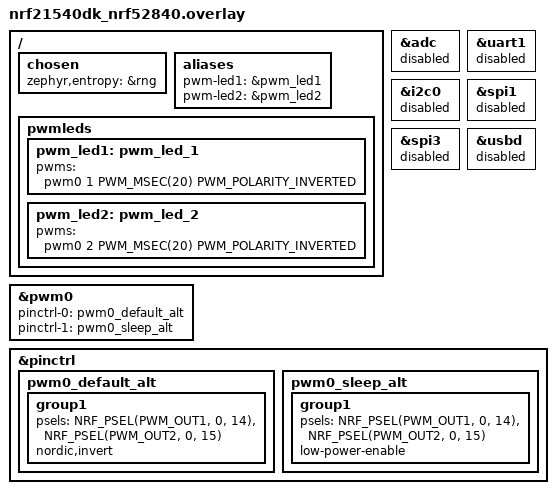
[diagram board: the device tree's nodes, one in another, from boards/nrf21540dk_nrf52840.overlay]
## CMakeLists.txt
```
#
# Copyright (c) 2022 Nordic Semiconductor ASA
#
# SPDX-License-Identifier: LicenseRef-Nordic-5-Clause
#

cmake_minimum_required(VERSION 3.20.0)

find_package(Zephyr HINTS $ENV{ZEPHYR_BASE})

project(matter-window-app)

# Enable GNU STD support and initialize the Matter Data Model.
include(${ZEPHYR_CONNECTEDHOMEIP_MODULE_DIR}/config/nrfconnect/app/enable-gnu-std.cmake)
include(${ZEPHYR_CONNECTEDHOMEIP_MODULE_DIR}/src/app/chip_data_model.cmake)

# NORDIC SDK APP START

# Include all source files that are located in the Matter common directory.
include(${ZEPHYR_NRF_MODULE_DIR}/samples/matter/common/cmake/source_common.cmake)

target_include_directories(app PRIVATE
    src
    ${CONFIG_NCS_SAMPLE_MATTER_ZAP_FILES_PATH}
)

target_sources(app PRIVATE
    src/app_task.cpp
    src/window_covering.cpp
    src/main.cpp
    src/zcl_callbacks.cpp
)

chip_configure_data_model(app
    INCLUDE_SERVER
    BYPASS_IDL
    GEN_DIR ${CONFIG_NCS_SAMPLE_MATTER_ZAP_FILES_PATH}/zap-generated
    ZAP_FILE ${CMAKE_CURRENT_SOURCE_DIR}/${CONFIG_NCS_SAMPLE_MATTER_ZAP_FILES_PATH}/window-app.zap
)
# NORDIC SDK APP END
```

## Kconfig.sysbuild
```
#
# Copyright (c) 2023 Nordic Semiconductor ASA
#
# SPDX-License-Identifier: LicenseRef-Nordic-5-Clause
#

config WIFI_NRF70
	default y if BOARD_NRF7002DK

#### Radio core selection
config NRF_DEFAULT_IPC_RADIO
	default y

# Enable IEEE802.15.4 serialization to network core
# This config automatically pulls in the `overlay-802154.conf` in the ipc_radio image
config NETCORE_IPC_RADIO_IEEE802154
	default y if SOC_SERIES_NRF53X && !WIFI_NRF70

# Enable Bluetooth serialization to network core
# This config automatically pulls in the `overlay-bt_hci_ipc.conf` in the ipc_radio image
config NETCORE_IPC_RADIO_BT_HCI_IPC
	default y if SOC_SERIES_NRF53X

#### Bootloader
choice BOOTLOADER
	default BOOTLOADER_MCUBOOT if !BOARD_NRF21540DK
endchoice

if BOOTLOADER_MCUBOOT

#### DFU multi-image support
config DFU_MULTI_IMAGE_PACKAGE_BUILD
	default y

config DFU_MULTI_IMAGE_PACKAGE_APP
	default y

config PM_EXTERNAL_FLASH_MCUBOOT_SECONDARY
	default y

#### DFU network core configuration
if SOC_SERIES_NRF53X

config MCUBOOT_UPDATEABLE_IMAGES
	default 2

choice MCUBOOT_MODE
	default MCUBOOT_MODE_OVERWRITE_ONLY
endchoice

choice BOOT_SIGNATURE_TYPE
	default BOOT_SIGNATURE_TYPE_RSA
endchoice

config SECURE_BOOT_NETCORE
	default y

config NETCORE_APP_UPDATE
	default y

config DFU_MULTI_IMAGE_PACKAGE_NET
	default y

endif # SOC_SERIES_NRF53X

if BOARD_NRF54L15DK_NRF54L15_CPUAPP_NS

# Disable checking the external drivers for NS build.
config PM_OVERRIDE_EXTERNAL_DRIVER_CHECK
	default y

# override the mcuboot pad size, because it is not set globally for NS build.
config PM_MCUBOOT_PAD
	default 0x800

endif # BOARD_NRF54L15DK_NRF54L15_CPUAPP_NS

endif # BOOTLOADER_MCUBOOT

#### Enable generating factory data
config MATTER_FACTORY_DATA_GENERATE
	default y if !BOARD_NRF21540DK

source "${ZEPHYR_BASE}/share/sysbuild/Kconfig"
```

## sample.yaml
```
sample:
  description: Matter Window Covering example
  name: Matter Window Covering
tests:
  sample.matter.window_cover.debug:
    sysbuild: true
    build_only: true
    integration_platforms:
      - nrf52840dk/nrf52840
      - nrf5340dk/nrf5340/cpuapp
      - nrf54l15dk/nrf54l15/cpuapp
      - nrf54l15dk/nrf54l15/cpuapp/ns
    platform_allow: nrf52840dk/nrf52840 nrf5340dk/nrf5340/cpuapp
      nrf54l15dk/nrf54l15/cpuapp nrf54l15dk/nrf54l15/cpuapp/ns
    tags: sysbuild ci_samples_matter
  sample.matter.window_cover.release:
    sysbuild: true
    build_only: true
    extra_args: FILE_SUFFIX=release
      SB_CONFIG_BOOTLOADER_MCUBOOT=y SB_CONFIG_PARTITION_MANAGER=y
    integration_platforms:
      - nrf52840dk/nrf52840
      - nrf5340dk/nrf5340/cpuapp
      - nrf54l15dk/nrf54l15/cpuapp
    platform_allow: nrf52840dk/nrf52840 nrf5340dk/nrf5340/cpuapp
      nrf54l15dk/nrf54l15/cpuapp
    tags: sysbuild ci_samples_matter
  sample.matter.window_cover.lto:
    sysbuild: true
    build_only: true
    extra_args: CONFIG_LTO=y CONFIG_ISR_TABLES_LOCAL_DECLARATION=y
    integration_platforms:
      - nrf52840dk/nrf52840
      - nrf5340dk/nrf5340/cpuapp
      - nrf54l15dk/nrf54l15/cpuapp
    platform_allow: nrf52840dk/nrf52840 nrf5340dk/nrf5340/cpuapp
      nrf54l15dk/nrf54l15/cpuapp
    tags: sysbuild ci_samples_matter
  sample.matter.window_cover.release.nrf54l15.power_consumption:
    sysbuild: true
    build_only: true
    extra_args: FILE_SUFFIX=release CONFIG_NCS_SAMPLE_MATTER_LEDS=n
      CONFIG_NCS_SAMPLE_MATTER_WATCHDOG=n
    integration_platforms:
      - nrf54l15dk/nrf54l15/cpuapp
    platform_allow: nrf54l15dk/nrf54l15/cpuapp
    tags: sysbuild ci_samples_matter
```

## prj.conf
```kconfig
#
# Copyright (c) 2022 Nordic Semiconductor ASA
#
# SPDX-License-Identifier: LicenseRef-Nordic-5-Clause
#

# This sample uses Kconfig.defaults to set options common for all
# samples. This file should contain only options specific for this sample
# or overrides of default values.

# Enable CHIP
CONFIG_CHIP=y
CONFIG_CHIP_PROJECT_CONFIG="src/chip_project_config.h"
# 32784 == 0x8010 (example window-app)
CONFIG_CHIP_DEVICE_PRODUCT_ID=32784
CONFIG_STD_CPP17=y

# Enable Matter pairing automatically on application start.
CONFIG_CHIP_ENABLE_PAIRING_AUTOSTART=y

# Enable Matter extended announcement and increase duration to 1 hour.
CONFIG_CHIP_BLE_EXT_ADVERTISING=y
CONFIG_CHIP_BLE_ADVERTISING_DURATION=60

# Add support for LEDs and buttons on Nordic development kits
CONFIG_DK_LIBRARY=y

# PWM support
CONFIG_PWM=y

# OpenThread configs
CONFIG_OPENTHREAD_NORDIC_LIBRARY_MTD=y
CONFIG_OPENTHREAD_MTD=y
CONFIG_OPENTHREAD_FTD=n
CONFIG_CHIP_ENABLE_ICD_SUPPORT=y
CONFIG_CHIP_THREAD_SSED=y
CONFIG_CHIP_ICD_SLOW_POLL_INTERVAL=500
CONFIG_CHIP_ICD_FAST_POLLING_INTERVAL=500

# Bluetooth Low Energy configuration
CONFIG_BT_DEVICE_NAME="MatterWinCov"

# Suspend devices when the CPU goes into sleep
CONFIG_PM_DEVICE=y

# Stack size settings
CONFIG_IEEE802154_NRF5_RX_STACK_SIZE=1024

# Other settings
CONFIG_THREAD_NAME=y
CONFIG_MPU_STACK_GUARD=y
CONFIG_RESET_ON_FATAL_ERROR=n
CONFIG_CHIP_LIB_SHELL=y
CONFIG_NCS_SAMPLE_MATTER_TEST_SHELL=y

# Reduce application size
CONFIG_USE_SEGGER_RTT=n

# Enable Factory Data feature
CONFIG_CHIP_FACTORY_DATA=y
CONFIG_CHIP_FACTORY_DATA_BUILD=y
```

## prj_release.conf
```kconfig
#
# Copyright (c) 2022 Nordic Semiconductor ASA
#
# SPDX-License-Identifier: LicenseRef-Nordic-5-Clause
#

# This sample uses Kconfig.defaults to set options common for all
# samples. This file should contain only options specific for this sample
# or overrides of default values.

# Enable CHIP
CONFIG_CHIP=y
CONFIG_CHIP_PROJECT_CONFIG="src/chip_project_config.h"
# 32784 == 0x8010 (example window-app)
CONFIG_CHIP_DEVICE_PRODUCT_ID=32784
CONFIG_STD_CPP17=y

# Enable Matter pairing automatically on application start.
CONFIG_CHIP_ENABLE_PAIRING_AUTOSTART=y

# Enable Matter extended announcement and increase duration to 1 hour.
CONFIG_CHIP_BLE_EXT_ADVERTISING=y
CONFIG_CHIP_BLE_ADVERTISING_DURATION=60

# Add support for LEDs and buttons on Nordic development kits
CONFIG_DK_LIBRARY=y

# Try to disable unused RAM blocks to reduce power consumption
CONFIG_RAM_POWER_DOWN_LIBRARY=y

# PWM support
CONFIG_PWM=y

# OpenThread configs
CONFIG_OPENTHREAD_NORDIC_LIBRARY_MTD=y
CONFIG_OPENTHREAD_MTD=y
CONFIG_OPENTHREAD_FTD=n
CONFIG_CHIP_ENABLE_ICD_SUPPORT=y
CONFIG_CHIP_THREAD_SSED=y
CONFIG_CHIP_ICD_SLOW_POLL_INTERVAL=500
CONFIG_CHIP_ICD_FAST_POLLING_INTERVAL=500

# Bluetooth Low Energy configuration
CONFIG_BT_DEVICE_NAME="MatterWinCov"

# Suspend devices when the CPU goes into sleep
CONFIG_PM_DEVICE=y

# Stack size settings
CONFIG_IEEE802154_NRF5_RX_STACK_SIZE=1024

# Enable system reset on fatal error
CONFIG_RESET_ON_FATAL_ERROR=y

# Disable all debug features
CONFIG_USE_SEGGER_RTT=n
CONFIG_SHELL=n
CONFIG_OPENTHREAD_SHELL=n
CONFIG_CONSOLE=n
CONFIG_UART_CONSOLE=n
CONFIG_SERIAL=n
CONFIG_LOG=n
CONFIG_LOG_MODE_MINIMAL=n
CONFIG_ASSERT_VERBOSE=n
CONFIG_ASSERT_NO_FILE_INFO=y
CONFIG_PRINTK=n
CONFIG_PRINTK_SYNC=n
CONFIG_THREAD_NAME=n
CONFIG_BOOT_BANNER=n

# Enable Factory Data feature
CONFIG_CHIP_FACTORY_DATA=y
CONFIG_CHIP_FACTORY_DATA_BUILD=y

# Enable Watchdog
CONFIG_NCS_SAMPLE_MATTER_WATCHDOG=y
```

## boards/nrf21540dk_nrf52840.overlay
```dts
/* Copyright (c) 2021 Nordic Semiconductor ASA
 *
 * SPDX-License-Identifier: LicenseRef-Nordic-5-Clause
 */

/ {
	/*
	* In some default configurations within the nRF Connect SDK,
	* e.g. on nRF52840, the chosen zephyr,entropy node is &cryptocell.
	* This devicetree overlay ensures that default is overridden wherever it
	* is set, as this application uses the RNG node for entropy exclusively.
	*/
	chosen {
		zephyr,entropy = &rng;
	};

	/*
	* Configure LED2 and LED3 to show the state of the
	* window cover,by using the LED's brightness level.
	*/
	aliases {
		pwm-led1 = &pwm_led1;
		pwm-led2 = &pwm_led2;
	};

	pwmleds {
		pwm_led1: pwm_led_1 {
			pwms = <&pwm0 1 PWM_MSEC(20) PWM_POLARITY_INVERTED>;
		};
		pwm_led2: pwm_led_2 {
			pwms = <&pwm0 2 PWM_MSEC(20) PWM_POLARITY_INVERTED>;
		};
	};
};

/* Disable unused peripherals to reduce power consumption */
&adc {
	status = "disabled";
};
&uart1 {
	status = "disabled";
};
&i2c0 {
	status = "disabled";
};
&spi1 {
	status = "disabled";
};
&spi3 {
	status = "disabled";
};
&usbd {
	status = "disabled";
};

&pwm0 {
	pinctrl-0 = <&pwm0_default_alt>;
	pinctrl-1 = <&pwm0_sleep_alt>;
	pinctrl-names = "default", "sleep";
};

&pinctrl {
	pwm0_default_alt: pwm0_default_alt {
		group1 {
			psels = <NRF_PSEL(PWM_OUT1, 0, 14)>, <NRF_PSEL(PWM_OUT2, 0, 15)>;
			nordic,invert;
		};
	};

	pwm0_sleep_alt: pwm0_sleep_alt {
		group1 {
			psels = <NRF_PSEL(PWM_OUT1, 0, 14)>, <NRF_PSEL(PWM_OUT2, 0, 15)>;
			low-power-enable;
		};
	};
};
```

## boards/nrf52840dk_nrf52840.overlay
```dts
/* Copyright (c) 2021 Nordic Semiconductor ASA
 *
 * SPDX-License-Identifier: LicenseRef-Nordic-5-Clause
 */

/ {
	chosen {
		nordic,pm-ext-flash = &mx25r64;
	};
};


/ {
	/*
	* In some default configurations within the nRF Connect SDK,
	* e.g. on nRF52840, the chosen zephyr,entropy node is &cryptocell.
	* This devicetree overlay ensures that default is overridden wherever it
	* is set, as this application uses the RNG node for entropy exclusively.
	*/
	chosen {
		zephyr,entropy = &rng;
	};

	/*
	* Configure LED2 and LED3 to show the state of the
	* window cover,by using the LED's brightness level.
	*/
	aliases {
		pwm-led1 = &pwm_led1;
		pwm-led2 = &pwm_led2;
	};

	pwmleds {
		pwm_led1: pwm_led_1 {
			pwms = <&pwm0 1 PWM_MSEC(20) PWM_POLARITY_INVERTED>;
		};
		pwm_led2: pwm_led_2 {
			pwms = <&pwm0 2 PWM_MSEC(20) PWM_POLARITY_INVERTED>;
		};
	};
};

/* Disable unused peripherals to reduce power consumption */
&adc {
	status = "disabled";
};
&uart1 {
	status = "disabled";
};
&i2c0 {
	status = "disabled";
};
&spi1 {
	status = "disabled";
};
&spi3 {
	status = "disabled";
};
&usbd {
	status = "disabled";
};

&pwm0 {
	pinctrl-0 = <&pwm0_default_alt>;
	pinctrl-1 = <&pwm0_sleep_alt>;
	pinctrl-names = "default", "sleep";
};

&pinctrl {
	pwm0_default_alt: pwm0_default_alt {
		group1 {
			psels = <NRF_PSEL(PWM_OUT1, 0, 14)>, <NRF_PSEL(PWM_OUT2, 0, 15)>;
			nordic,invert;
		};
	};

	pwm0_sleep_alt: pwm0_sleep_alt {
		group1 {
			psels = <NRF_PSEL(PWM_OUT1, 0, 14)>, <NRF_PSEL(PWM_OUT2, 0, 15)>;
			low-power-enable;
		};
	};
};
```

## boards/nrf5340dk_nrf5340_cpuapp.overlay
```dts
/*
 * Copyright (c) 2021 Nordic Semiconductor ASA
 *
 * SPDX-License-Identifier: LicenseRef-Nordic-5-Clause
 */

#include <zephyr/dt-bindings/ipc_service/static_vrings.h>

/ {
	chosen {
		nordic,pm-ext-flash = &mx25r64;
	};

	/*
	* Configure LED2 and LED3 to show the state of the
	* window cover,by using the LED's brightness level.
	*/
	aliases {
		pwm-led1 = &pwm_led1;
		pwm-led2 = &pwm_led2;
	};

	pwmleds {
		compatible = "pwm-leds";
		pwm_led1: pwm_led_1 {
			pwms = <&pwm0 1 PWM_MSEC(20) PWM_POLARITY_INVERTED>;
		};
		pwm_led2: pwm_led_2 {
			pwms = <&pwm0 2 PWM_MSEC(20) PWM_POLARITY_INVERTED>;
		};
	};
};

/* Set IPC thread priority to the highest value to not collide with other threads. */
&ipc0 {
    zephyr,priority = <0 PRIO_COOP>;
};

/* Disable unused peripherals to reduce power consumption */
&adc {
	status = "disabled";
};
&i2c1 {
	status = "disabled";
};
&spi2 {
	status = "disabled";
};
&usbd {
	status = "disabled";
};

&pwm0 {
	pinctrl-0 = <&pwm0_default_alt>;
	pinctrl-1 = <&pwm0_sleep_alt>;
	pinctrl-names = "default", "sleep";
};

&pinctrl {
	pwm0_default_alt: pwm0_default_alt {
		group1 {
			psels = <NRF_PSEL(PWM_OUT1, 0, 29)>, <NRF_PSEL(PWM_OUT2, 0, 30)>;
			nordic,invert;
		};
	};

	pwm0_sleep_alt: pwm0_sleep_alt {
		group1 {
			psels = <NRF_PSEL(PWM_OUT1, 0, 29)>, <NRF_PSEL(PWM_OUT2, 0, 30)>;
			low-power-enable;
		};
	};
};
```

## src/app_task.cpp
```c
/*
 * Copyright (c) 2022 Nordic Semiconductor ASA
 *
 * SPDX-License-Identifier: LicenseRef-Nordic-5-Clause
 */

#include "app_task.h"

#include "window_covering.h"

#include "app/matter_init.h"
#include "app/task_executor.h"

#ifdef CONFIG_CHIP_OTA_REQUESTOR
#include "dfu/ota/ota_util.h"
#endif

#include <app/clusters/identify-server/identify-server.h>
#include <app/server/OnboardingCodesUtil.h>

#include <zephyr/logging/log.h>

LOG_MODULE_DECLARE(app, CONFIG_CHIP_APP_LOG_LEVEL);

using namespace ::chip;
using namespace ::chip::app;
using namespace ::chip::DeviceLayer;

namespace
{
Identify sIdentify = { WindowCovering::Endpoint(), AppTask::IdentifyStartHandler, AppTask::IdentifyStopHandler,
		       Clusters::Identify::IdentifyTypeEnum::kVisibleIndicator };

#define OPEN_BUTTON_MASK DK_BTN2_MSK
#define CLOSE_BUTTON_MASK DK_BTN3_MSK
} /* namespace */

void AppTask::IdentifyStartHandler(Identify *)
{
	Nrf::PostTask([] {
		WindowCovering::Instance().GetLiftIndicator().SuppressOutput();
		Nrf::GetBoard().GetLED(Nrf::DeviceLeds::LED2).Blink(Nrf::LedConsts::kIdentifyBlinkRate_ms);
	});
}

void AppTask::IdentifyStopHandler(Identify *)
{
	Nrf::PostTask([] {
		Nrf::GetBoard().GetLED(Nrf::DeviceLeds::LED2).Set(false);
		WindowCovering::Instance().GetLiftIndicator().ApplyLevel();
	});
}

void AppTask::ButtonEventHandler(Nrf::ButtonState state, Nrf::ButtonMask hasChanged)
{
	if (OPEN_BUTTON_MASK & hasChanged) {
		WindowButtonAction action =
			(OPEN_BUTTON_MASK & state) ? WindowButtonAction::Pressed : WindowButtonAction::Released;
		Nrf::PostTask([action] { OpenHandler(action); });
	}

	if (CLOSE_BUTTON_MASK & hasChanged) {
		WindowButtonAction action =
			(CLOSE_BUTTON_MASK & state) ? WindowButtonAction::Pressed : WindowButtonAction::Released;
		Nrf::PostTask([action] { CloseHandler(action); });
	}
}

void AppTask::OpenHandler(const WindowButtonAction &action)
{
	if (action == WindowButtonAction::Pressed) {
		Instance().mOpenButtonIsPressed = true;
		if (Instance().mCloseButtonIsPressed) {
			Instance().ToggleMoveType();
		}
	} else {
		if (!Instance().mCloseButtonIsPressed) {
			if (!Instance().mMoveTypeRecentlyChanged) {
				WindowCovering::Instance().SetSingleStepTarget(OperationalState::MovingUpOrOpen);
			} else {
				Instance().mMoveTypeRecentlyChanged = false;
			}
		}
		Instance().mOpenButtonIsPressed = false;
	}
}

void AppTask::CloseHandler(const WindowButtonAction &action)
{
	if (action == WindowButtonAction::Pressed) {
		Instance().mCloseButtonIsPressed = true;
		if (Instance().mOpenButtonIsPressed) {
			Instance().ToggleMoveType();
		}
	} else {
		if (!Instance().mOpenButtonIsPressed) {
			if (!Instance().mMoveTypeRecentlyChanged) {
				WindowCovering::Instance().SetSingleStepTarget(OperationalState::MovingDownOrClose);
			} else {
				Instance().mMoveTypeRecentlyChanged = false;
			}
		}
		Instance().mCloseButtonIsPressed = false;
	}
}

void AppTask::ToggleMoveType()
{
	if (WindowCovering::Instance().GetMoveType() == WindowCovering::MoveType::LIFT) {
		WindowCovering::Instance().SetMoveType(WindowCovering::MoveType::TILT);
		LOG_INF("Window covering move: tilt");
	} else {
		WindowCovering::Instance().SetMoveType(WindowCovering::MoveType::LIFT);
		LOG_INF("Window covering move: lift");
	}
	mMoveTypeRecentlyChanged = true;
}

CHIP_ERROR AppTask::Init()
{
	/* Initialize Matter stack */
	ReturnErrorOnFailure(Nrf::Matter::PrepareServer(Nrf::Matter::InitData{ .mPostServerInitClbk = [] {
		WindowCovering::Instance().PositionLEDUpdate(WindowCovering::MoveType::LIFT);
		WindowCovering::Instance().PositionLEDUpdate(WindowCovering::MoveType::TILT);
		return CHIP_NO_ERROR;
	} }));

	if (!Nrf::GetBoard().Init(ButtonEventHandler)) {
		LOG_ERR("User interface initialization failed.");
		return CHIP_ERROR_INCORRECT_STATE;
	}

	/* Register Matter event handler that controls the connectivity status LED based on the captured Matter network
	 * state. */
	ReturnErrorOnFailure(Nrf::Matter::RegisterEventHandler(Nrf::Board::DefaultMatterEventHandler, 0));

	return Nrf::Matter::StartServer();
}

CHIP_ERROR AppTask::StartApp()
{
	ReturnErrorOnFailure(Init());

	while (true) {
		Nrf::DispatchNextTask();
	}

	return CHIP_NO_ERROR;
}
```
